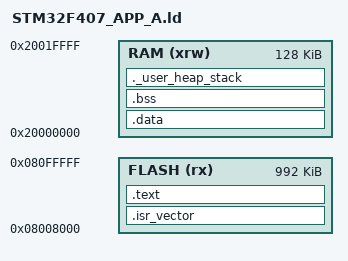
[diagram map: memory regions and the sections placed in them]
ENTRY(Reset_Handler)

_estack = ORIGIN(RAM) + LENGTH(RAM);

_Min_Heap_Size = 0x400;
_Min_Stack_Size = 0x800;

MEMORY
{
  FLASH (rx) : ORIGIN = 0x08008000, LENGTH = 992K
  RAM   (xrw): ORIGIN = 0x20000000, LENGTH = 128K
}

SECTIONS
{
  .isr_vector :
  {
    . = ALIGN(4);
    KEEP(*(.isr_vector))
    . = ALIGN(4);
  } > FLASH

  .text :
  {
    . = ALIGN(4);
    *(.text)
    *(.text*)
    *(.rodata)
    *(.rodata*)
    *(.glue_7)
    *(.glue_7t)
    *(.eh_frame)
    KEEP (*(.init))
    KEEP (*(.fini))
    . = ALIGN(4);
    _etext = .;
  } > FLASH

  .data : AT (_etext)
  {
    . = ALIGN(4);
    _sdata = .;
    *(.data)
    *(.data*)
    . = ALIGN(4);
    _edata = .;
  } > RAM

  .bss :
  {
    . = ALIGN(4);
    _sbss = .;
    *(.bss)
    *(.bss*)
    *(COMMON)
    . = ALIGN(4);
    _ebss = .;
  } > RAM

  ._user_heap_stack :
  {
    . = ALIGN(8);
    PROVIDE(end = .);
    PROVIDE(_end = .);
    . = . + _Min_Heap_Size;
    . = . + _Min_Stack_Size;
    . = ALIGN(8);
  } > RAM

  /DISCARD/ :
  {
    libc.a ( * )
    libm.a ( * )
    libgcc.a ( * )
  }
}
